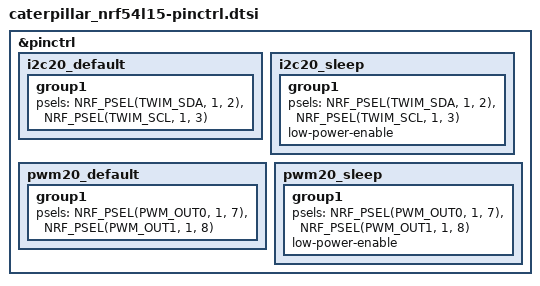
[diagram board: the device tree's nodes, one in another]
&pinctrl {
	i2c20_default: i2c20_default {
		group1 {
			psels = <NRF_PSEL(TWIM_SDA, 1, 2)>,
				    <NRF_PSEL(TWIM_SCL, 1, 3)>;
		};
	};

	i2c20_sleep: i2c20_sleep {
		group1 {
			psels = <NRF_PSEL(TWIM_SDA, 1, 2)>,
				    <NRF_PSEL(TWIM_SCL, 1, 3)>;
			low-power-enable;
		};
	};

	pwm20_default: pwm20_default {
		group1 {
			/* PWM_OUT0 = IN1, PWM_OUT1 = IN2 */
			psels = <NRF_PSEL(PWM_OUT0, 1, 7)>,
				    <NRF_PSEL(PWM_OUT1, 1, 8)>;
		};
	};

	pwm20_sleep: pwm20_sleep {
		group1 {
			psels = <NRF_PSEL(PWM_OUT0, 1, 7)>,
				    <NRF_PSEL(PWM_OUT1, 1, 8)>;
			low-power-enable;
		};
	};
};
